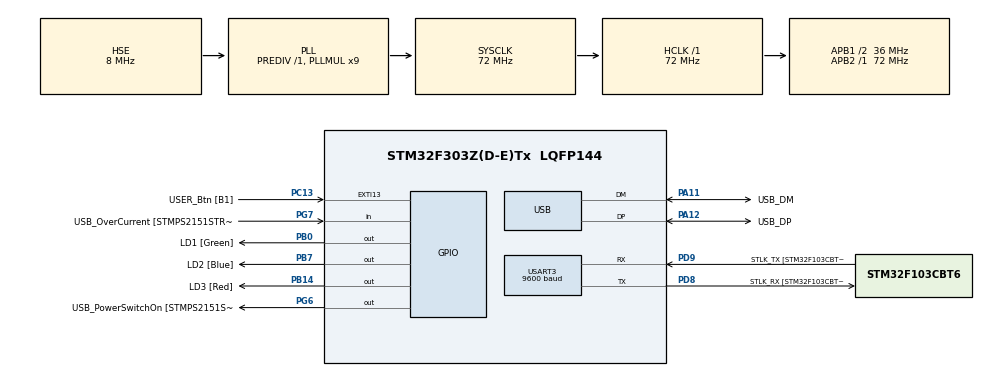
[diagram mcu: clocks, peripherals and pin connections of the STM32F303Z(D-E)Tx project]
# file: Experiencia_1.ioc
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Mcu.Family=STM32F3
Mcu.Name=STM32F303Z(D-E)Tx
Mcu.Package=LQFP144
NVIC.PriorityGroup=NVIC_PRIORITYGROUP_4
NVIC.USB_LP_CAN_RX0_IRQn=true\:0\:0\:false\:false\:true\:true\:true\:true
PA11.GPIO_Label=USB_DM
PA11.Mode=Device
PA11.Signal=USB_DM
PA12.GPIO_Label=USB_DP
PA12.Mode=Device
PA12.Signal=USB_DP
PA13.GPIO_Label=TMS
PA13.Mode=Serial_Wire
PA13.Signal=SYS_JTMS-SWDIO
PA14.GPIO_Label=TCK
PA14.Mode=Serial_Wire
PA14.Signal=SYS_JTCK-SWCLK
PB0.GPIO_Label=LD1 [Green]
PB0.Signal=GPIO_Output
PB14.GPIO_Label=LD3 [Red]
PB14.Signal=GPIO_Output
PB3.GPIO_Label=SWO
PB3.Signal=SYS_JTDO-TRACESWO
PB7.GPIO_Label=LD2 [Blue]
PB7.Signal=GPIO_Output
PC13.GPIO_Label=USER_Btn [B1]
PC13.Signal=GPXTI13
PC14-OSC32_IN.Mode=LSE-External-Oscillator
PC14-OSC32_IN.Signal=RCC_OSC32_IN
PC15-OSC32_OUT.Mode=LSE-External-Oscillator
PC15-OSC32_OUT.Signal=RCC_OSC32_OUT
PD8.GPIO_Label=STLK_RX [STM32F103CBT6_PA3]
PD8.Mode=Asynchronous
PD8.Signal=USART3_TX
PD9.GPIO_Label=STLK_TX [STM32F103CBT6_PA2]
PD9.Mode=Asynchronous
PD9.Signal=USART3_RX
PF0-OSC_IN.GPIO_Label=MCO [STM32F103CBT6_PA8]
PF0-OSC_IN.Mode=HSE-External-Clock-Source
PF0-OSC_IN.Signal=RCC_OSC_IN
PG6.GPIO_Label=USB_PowerSwitchOn [STMPS2151STR_EN]
PG6.Signal=GPIO_Output
PG7.GPIO_Label=USB_OverCurrent [STMPS2151STR_FAULT]
PG7.Signal=GPIO_Input
ProjectManager.HeapSize=0x200
ProjectManager.StackSize=0x400
ProjectManager.TargetToolchain=STM32CubeIDE
RCC.AHBFreq_Value=72000000
RCC.APB1CLKDivider=RCC_HCLK_DIV2
RCC.APB1Freq_Value=36000000
RCC.APB1TimFreq_Value=72000000
RCC.APB2Freq_Value=72000000
RCC.APB2TimFreq_Value=72000000
RCC.CortexFreq_Value=72000000
RCC.HCLKFreq_Value=72000000
RCC.HSE_VALUE=8000000
RCC.HSI_VALUE=8000000
RCC.PLLMUL=RCC_PLL_MUL9
RCC.PRESCALERUSB=RCC_USBCLKSOURCE_PLL_DIV1_5
RCC.SYSCLKFreq_VALUE=72000000
RCC.SYSCLKSourceVirtual=RCC_SYSCLKSOURCE_PLLCLK
RCC.USBFreq_Value=48000000
USART3.BaudRate=9600
USART3.VirtualMode-Asynchronous=VM_ASYNC
VP_RTC_VS_RTC_Activate.Mode=RTC_Enabled
board=NUCLEO-F303ZE

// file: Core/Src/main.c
/* USER CODE BEGIN Header */
/**
  ******************************************************************************
  * @file           : main.c
  * @brief          : Main program body
  ******************************************************************************
  * @attention
  *
  * Copyright (c) 2024 STMicroelectronics.
  * All rights reserved.
  *
  * This software is licensed under terms that can be found in the LICENSE file
  * in the root directory of this software component.
  * If no LICENSE file comes with this software, it is provided AS-IS.
  *
  ******************************************************************************
  */
/* USER CODE END Header */
#include "main.h"
#include "rtc.h"
#include "usart.h"
#include "usb.h"
#include "gpio.h"

void SystemClock_Config(void);

int main(void)
{

  /* MCU Configuration--------------------------------------------------------*/

  /* Reset of all peripherals, Initializes the Flash interface and the Systick. */
  HAL_Init();

  /* Configure the system clock */
  SystemClock_Config();

  /* Initialize all configured peripherals */
  MX_GPIO_Init();
  MX_RTC_Init();
  MX_USART3_UART_Init();
  MX_USB_PCD_Init();
  /* USER CODE BEGIN 2 */

  HAL_UART_MspInit(&huart3);
  char message[5] = {0};

  /* USER CODE END 2 */

  /* Infinite loop */
  while (1)
  {

    /* USER CODE BEGIN 3 */
	USART_receive_data(message, 1);
	USART_transmit_data(message);
  }
  /* USER CODE END 3 */
}

void SystemClock_Config(void)
{
  RCC_OscInitTypeDef RCC_OscInitStruct = {0};
  RCC_ClkInitTypeDef RCC_ClkInitStruct = {0};
  RCC_PeriphCLKInitTypeDef PeriphClkInit = {0};

  /** Initializes the RCC Oscillators according to the specified parameters
  * in the RCC_OscInitTypeDef structure.
  */
  RCC_OscInitStruct.OscillatorType = RCC_OSCILLATORTYPE_LSI|RCC_OSCILLATORTYPE_HSE;
  RCC_OscInitStruct.HSEState = RCC_HSE_BYPASS;
  RCC_OscInitStruct.HSIState = RCC_HSI_ON;
  RCC_OscInitStruct.LSIState = RCC_LSI_ON;
  RCC_OscInitStruct.PLL.PLLState = RCC_PLL_ON;
  RCC_OscInitStruct.PLL.PLLSource = RCC_PLLSOURCE_HSE;
  RCC_OscInitStruct.PLL.PLLMUL = RCC_PLL_MUL9;
  RCC_OscInitStruct.PLL.PREDIV = RCC_PREDIV_DIV1;
  if (HAL_RCC_OscConfig(&RCC_OscInitStruct) != HAL_OK)
  {
    Error_Handler();
  }

  /** Initializes the CPU, AHB and APB buses clocks
  */
  RCC_ClkInitStruct.ClockType = RCC_CLOCKTYPE_HCLK|RCC_CLOCKTYPE_SYSCLK
                              |RCC_CLOCKTYPE_PCLK1|RCC_CLOCKTYPE_PCLK2;
  RCC_ClkInitStruct.SYSCLKSource = RCC_SYSCLKSOURCE_PLLCLK;
  RCC_ClkInitStruct.AHBCLKDivider = RCC_SYSCLK_DIV1;
  RCC_ClkInitStruct.APB1CLKDivider = RCC_HCLK_DIV2;
  RCC_ClkInitStruct.APB2CLKDivider = RCC_HCLK_DIV1;

  if (HAL_RCC_ClockConfig(&RCC_ClkInitStruct, FLASH_LATENCY_2) != HAL_OK)
  {
    Error_Handler();
  }
  PeriphClkInit.PeriphClockSelection = RCC_PERIPHCLK_USB|RCC_PERIPHCLK_USART3
                              |RCC_PERIPHCLK_RTC;
  PeriphClkInit.Usart3ClockSelection = RCC_USART3CLKSOURCE_PCLK1;
  PeriphClkInit.RTCClockSelection = RCC_RTCCLKSOURCE_LSI;
  PeriphClkInit.USBClockSelection = RCC_USBCLKSOURCE_PLL_DIV1_5;
  if (HAL_RCCEx_PeriphCLKConfig(&PeriphClkInit) != HAL_OK)
  {
    Error_Handler();
  }
}

void Error_Handler(void)
{
  __disable_irq();
  while (1)
  {
  }
}
